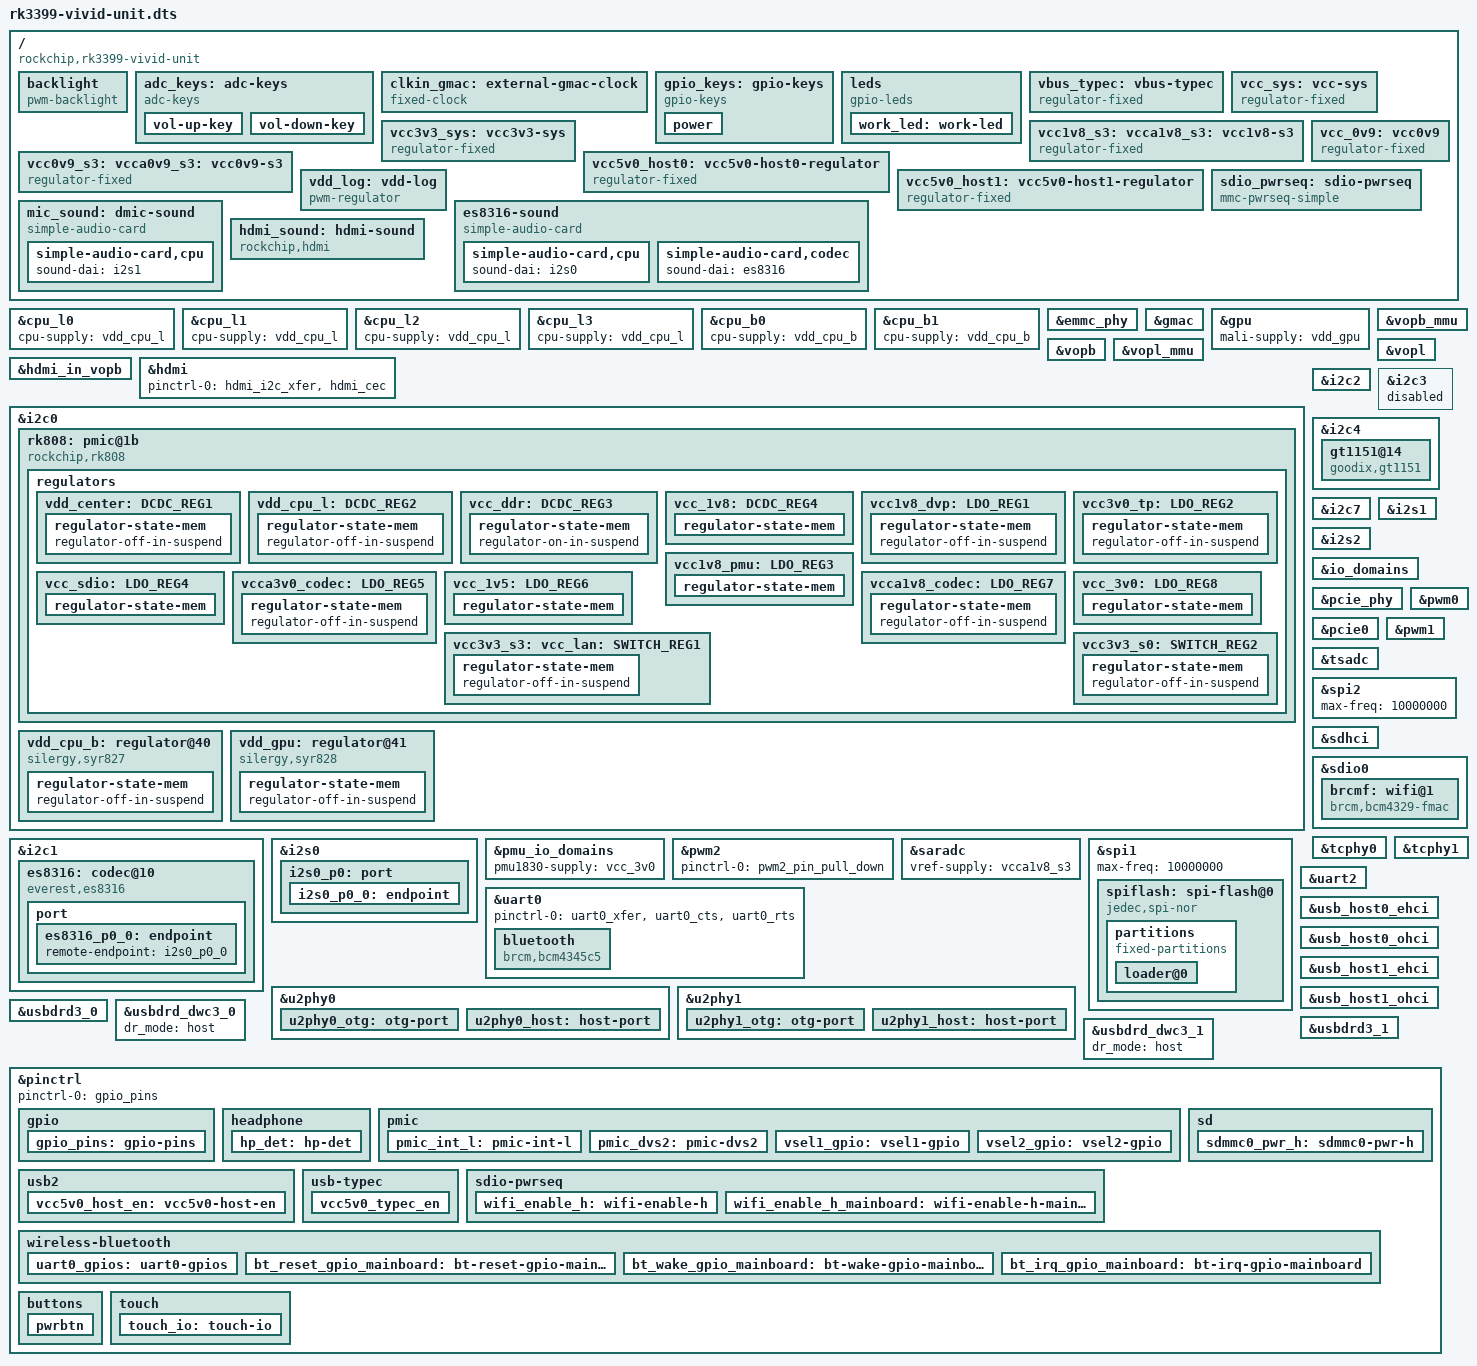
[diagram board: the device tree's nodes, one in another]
// SPDX-License-Identifier: (GPL-2.0+ OR MIT)
/*
 * Copyright (c) 2022 Biandenghuo Co., Ltd.
 */

/dts-v1/;
#include "dt-bindings/pwm/pwm.h"
#include "dt-bindings/input/input.h"
#include "rk3399.dtsi"
#include "rk3399-opp.dtsi"

/ {
	compatible = "rockchip,rk3399-vivid-unit", "rockchip,rk3399";

	backlight: backlight {
		compatible = "pwm-backlight";
		brightness-levels = <0 255>;
		num-interpolated-steps = <255>;
		default-brightness-level = <200>;
		pwms = <&pwm0 0 25000 0>, <&pwm1 0 1000000 0>;
	};

	adc_keys: adc-keys {
                compatible = "adc-keys";
                io-channels = <&saradc 1>;
                io-channel-names = "buttons";
                keyup-threshold-microvolt = <1800000>;
                poll-interval = <100>;

                vol-up-key {
                        label = "volume up";
                        linux,code = <KEY_VOLUMEUP>;
                        press-threshold-microvolt = <1000>;
                };

                vol-down-key {
                        label = "volume down";
                        linux,code = <KEY_VOLUMEDOWN>;
                        press-threshold-microvolt = <170000>;
                };
	};
	
	clkin_gmac: external-gmac-clock {
		compatible = "fixed-clock";
		clock-frequency = <125000000>;
		clock-output-names = "clkin_gmac";
		#clock-cells = <0>;
	};
	
	gpio_keys: gpio-keys {
                compatible = "gpio-keys";
                autorepeat;
                pinctrl-names = "default";
                pinctrl-0 = <&pwrbtn>;

                power {
                        debounce-interval = <100>;
                        gpios = <&gpio0 5 GPIO_ACTIVE_LOW>;
                        label = "GPIO Key Power";
                        linux,code = <KEY_POWER>;
                        wakeup-source;
                };
        };

	leds {
                status = "okay";
                compatible = "gpio-leds";
                work_led: work-led {
                        label = "work-led";
                        gpios = <&gpio4 21 GPIO_ACTIVE_LOW>; /*GPIO4_C5*/
                        linux,default-trigger = "mmc0";
                        default-state = "on";
                };
        };

	vbus_typec: vbus-typec {
		compatible = "regulator-fixed";
		regulator-name = "vbus_typec";
		regulator-always-on;
		regulator-boot-on;
		regulator-min-microvolt = <5000000>;
		regulator-max-microvolt = <5000000>;
	};
	
	vcc_sys: vcc-sys {
		compatible = "regulator-fixed";
		regulator-name = "vcc_sys";
		regulator-always-on;
		regulator-boot-on;
		regulator-min-microvolt = <5000000>;
		regulator-max-microvolt = <5000000>;
		vin-supply = <&vbus_typec>;
	};

	vcc3v3_sys: vcc3v3-sys {
		compatible = "regulator-fixed";
		regulator-name = "vcc3v3_sys";
		regulator-always-on;
		regulator-boot-on;
		regulator-min-microvolt = <3300000>;
		regulator-max-microvolt = <3300000>;
		vin-supply = <&vcc_sys>;
	};	
	
	/* switched by pmic_sleep */
	vcc1v8_s3: vcca1v8_s3: vcc1v8-s3 {
		compatible = "regulator-fixed";
		regulator-name = "vcc1v8_s3";
		regulator-always-on;
		regulator-boot-on;
		regulator-min-microvolt = <1800000>;
		regulator-max-microvolt = <1800000>;
		vin-supply = <&vcc_1v8>;
	};
	
	vcc_0v9: vcc0v9 {
		compatible = "regulator-fixed";
		regulator-name = "vcc0v9";
		regulator-always-on;
		regulator-boot-on;
		regulator-min-microvolt = <900000>;
		regulator-max-microvolt = <900000>;
		vin-supply = <&vcc3v3_sys>;
	};

	/* switched by pmic_sleep */
	vcc0v9_s3: vcca0v9_s3: vcc0v9-s3 {
		compatible = "regulator-fixed";
		regulator-name = "vcc0v9_s3";
		regulator-always-on;
		regulator-boot-on;
		regulator-min-microvolt = <900000>;
		regulator-max-microvolt = <900000>;
		vin-supply = <&vcc_0v9>;
	};
	
	vcc5v0_host0: vcc5v0-host0-regulator {
		compatible = "regulator-fixed";
		enable-active-high;
		gpio = <&gpio1 RK_PA0 GPIO_ACTIVE_HIGH>;
		pinctrl-names = "default";
		pinctrl-0 = <&vcc5v0_host_en>;
		regulator-name = "vcc5v0_host0";
		regulator-always-on;
		vin-supply = <&vcc_sys>;
	};
	
	vcc5v0_host1: vcc5v0-host1-regulator {
		compatible = "regulator-fixed";
		enable-active-high;
		gpio = <&gpio1 RK_PA3 GPIO_ACTIVE_HIGH>;
		pinctrl-names = "default";
		pinctrl-0 = <&vcc5v0_typec_en>;
		regulator-name = "vcc5v0_host1";
		regulator-always-on;
		vin-supply = <&vcc_sys>;
	};

	vdd_log: vdd-log {
		compatible = "pwm-regulator";
		pwms = <&pwm2 0 25000 1>;
		regulator-name = "vdd_log";
		regulator-always-on;
		regulator-boot-on;
		regulator-min-microvolt = <800000>;
		regulator-max-microvolt = <1400000>;
		vin-supply = <&vcc_sys>;
	};

	sdio_pwrseq: sdio-pwrseq {
                compatible = "mmc-pwrseq-simple";
                clocks = <&rk808 1>;
                clock-names = "ext_clock";
                pinctrl-names = "default";
                pinctrl-0 = <&wifi_enable_h>;
                reset-gpios = <&gpio0 10 GPIO_ACTIVE_LOW>; /* GPIO0_B2 */
        };

	mic_sound: dmic-sound {
                compatible = "simple-audio-card";
                simple-audio-card,format = "i2s";
                simple-audio-card,name = "rockchip,rk-mic-sound";
                simple-audio-card,mclk-fs = <256>;
                simple-audio-card,cpu {
                        sound-dai = <&i2s1>;
                };
        };

	es8316-sound {
                compatible = "simple-audio-card";
                simple-audio-card,format = "i2s";
                simple-audio-card,name = "rockchip,es8316-codec";
                simple-audio-card,mclk-fs = <256>;
                simple-audio-card,widgets =
                        "Microphone", "Mic Jack",
                        "Headphone", "Headphone Jack";
                simple-audio-card,routing =
                        "Mic Jack", "Mic Bias",
                        "MIC2", "Mic Jack",
                        "Headphone Jack", "HPOL",
                        "Headphone Jack", "HPOR";
                simple-audio-card,cpu {
                        sound-dai = <&i2s0>;
                };
                simple-audio-card,codec {
                        sound-dai = <&es8316>;
                };
        };

	hdmi_sound: hdmi-sound {
                status = "okay";
                compatible = "rockchip,hdmi";
                rockchip,mclk-fs = <256>;
                rockchip,card-name = "rockchip-hdmi0";
                rockchip,cpu = <&i2s2>;
                rockchip,codec = <&hdmi>;
                rockchip,jack-det;
        };
};

&cpu_l0 {
	cpu-supply = <&vdd_cpu_l>;
};

&cpu_l1 {
	cpu-supply = <&vdd_cpu_l>;
};

&cpu_l2 {
	cpu-supply = <&vdd_cpu_l>;
};

&cpu_l3 {
	cpu-supply = <&vdd_cpu_l>;
};

&cpu_b0 {
	cpu-supply = <&vdd_cpu_b>;
};

&cpu_b1 {
	cpu-supply = <&vdd_cpu_b>;
};

//&dsipanel {
//	reset-gpios = <&gpio4 29 GPIO_ACTIVE_LOW>;      /*GPIO4_D5*/
//	enable-gpios = <&gpio1 13 GPIO_ACTIVE_HIGH>;    /*GPIO1_B5*/
//
//	prepare-delay-ms = <20>;
//	reset-delay-ms = <20>;
//	init-delay-ms = <20>;
//	enable-delay-ms = <20>;
//	disable-delay-ms = <20>;
//	unprepare-delay-ms = <20>;
//};
//
//&dsi_in_vopl {
//	status = "okay";
//};

&emmc_phy {
	status = "okay";
};

&gmac {
	assigned-clocks = <&cru SCLK_RMII_SRC>;
	assigned-clock-parents = <&clkin_gmac>;
	clock_in_out = "input";
	phy-supply = <&vcc_lan>;
	phy-mode = "rgmii";
	pinctrl-names = "default";
	pinctrl-0 = <&rgmii_pins>;
	snps,reset-gpio = <&gpio3 RK_PB7 GPIO_ACTIVE_LOW>;
	snps,reset-active-low;
	snps,reset-delays-us = <0 10000 50000>;
	tx_delay = <0x28>;
	rx_delay = <0x11>;
	status = "okay";
};

&gpu {
	mali-supply = <&vdd_gpu>;
	status = "okay";
};

&vopb_mmu {
	status = "okay";
};

&vopb {
	status = "okay";
	assigned-clocks = <&cru DCLK_VOP0_DIV>;
	assigned-clock-parents = <&cru PLL_CPLL>;
};

&vopl_mmu {
	status = "okay";
};

&vopl {
	status = "okay";
	assigned-clocks = <&cru DCLK_VOP1_DIV>;
	assigned-clock-parents = <&cru PLL_VPLL>;
};

&hdmi_in_vopb {
	status = "okay";
};

&hdmi {
        pinctrl-names = "default";
        pinctrl-0 = <&hdmi_i2c_xfer>, <&hdmi_cec>;
        #address-cells = <1>;
        #size-cells = <0>;
        #sound-dai-cells = <0>;
        status = "okay";
};

&hdmi_sound {
        status = "okay";
};

&i2c0 {
	clock-frequency = <400000>; 
	i2c-scl-rising-time-ns = <168>;
	i2c-scl-falling-time-ns = <4>;
	status = "okay";

	rk808: pmic@1b {
		compatible = "rockchip,rk808";
		reg = <0x1b>;
		interrupt-parent = <&gpio1>;
		interrupts = <21 IRQ_TYPE_LEVEL_LOW>;
		#clock-cells = <1>;
		clock-output-names = "xin32k", "rk808-clkout2";
		pinctrl-names = "default";
		pinctrl-0 = <&pmic_int_l &pmic_dvs2>;
		rockchip,system-power-controller;
		wakeup-source;

		vcc1-supply = <&vcc3v3_sys>;
		vcc2-supply = <&vcc3v3_sys>;
		vcc3-supply = <&vcc3v3_sys>;
		vcc4-supply = <&vcc3v3_sys>;
		vcc6-supply = <&vcc3v3_sys>;
		vcc7-supply = <&vcc3v3_sys>;
		vcc8-supply = <&vcc3v3_sys>;
		vcc9-supply = <&vcc3v3_sys>;
		vcc10-supply = <&vcc3v3_sys>;
		vcc11-supply = <&vcc3v3_sys>;
		vcc12-supply = <&vcc3v3_sys>;
		vddio-supply = <&vcc_3v0>;

		regulators {
			vdd_center: DCDC_REG1 {
				regulator-name = "vdd_center";
				regulator-always-on;
				regulator-boot-on;
				regulator-min-microvolt = <750000>;
				regulator-max-microvolt = <1350000>;
				regulator-ramp-delay = <6001>;
				regulator-state-mem {
					regulator-off-in-suspend;
				};
			};

			vdd_cpu_l: DCDC_REG2 {
				regulator-name = "vdd_cpu_l";
				regulator-always-on;
				regulator-boot-on;
				regulator-min-microvolt = <750000>;
				regulator-max-microvolt = <1350000>;
				regulator-ramp-delay = <6001>;
				regulator-state-mem {
					regulator-off-in-suspend;
				};
			};

			vcc_ddr: DCDC_REG3 {
				regulator-name = "vcc_ddr";
				regulator-always-on;
				regulator-boot-on;
				regulator-state-mem {
					regulator-on-in-suspend;
				};
			};

			vcc_1v8: DCDC_REG4 {
				regulator-name = "vcc_1v8";
				regulator-always-on;
				regulator-boot-on;
				regulator-min-microvolt = <1800000>;
				regulator-max-microvolt = <1800000>;
				regulator-state-mem {
					regulator-on-in-suspend;
					regulator-suspend-microvolt = <1800000>;
				};
			};

			vcc1v8_dvp: LDO_REG1 {
				regulator-name = "vcc1v8_dvp";
				regulator-always-on;
				regulator-boot-on;
				regulator-min-microvolt = <1800000>;
				regulator-max-microvolt = <1800000>;
				regulator-state-mem {
					regulator-off-in-suspend;
				};
			};

			vcc3v0_tp: LDO_REG2 {
				regulator-name = "vcc3v0_tp";
				regulator-always-on;
				regulator-boot-on;
				regulator-min-microvolt = <3000000>;
				regulator-max-microvolt = <3000000>;
				regulator-state-mem {
					regulator-off-in-suspend;
				};
			};

			vcc1v8_pmu: LDO_REG3 {
				regulator-name = "vcc1v8_pmu";
				regulator-always-on;
				regulator-boot-on;
				regulator-min-microvolt = <1800000>;
				regulator-max-microvolt = <1800000>;
				regulator-state-mem {
					regulator-on-in-suspend;
					regulator-suspend-microvolt = <1800000>;
				};
			};

			vcc_sdio: LDO_REG4 {
				regulator-name = "vcc_sdio";
				regulator-always-on;
				regulator-boot-on;
				regulator-min-microvolt = <1800000>;
				regulator-max-microvolt = <3300000>;
				regulator-state-mem {
					regulator-on-in-suspend;
					regulator-suspend-microvolt = <3000000>;
				};
			};

			vcca3v0_codec: LDO_REG5 {
				regulator-name = "vcca3v0_codec";
				regulator-always-on;
				regulator-boot-on;
				regulator-min-microvolt = <3000000>;
				regulator-max-microvolt = <3000000>;
				regulator-state-mem {
					regulator-off-in-suspend;
				};
			};

			vcc_1v5: LDO_REG6 {
				regulator-name = "vcc_1v5";
				regulator-always-on;
				regulator-boot-on;
				regulator-min-microvolt = <1500000>;
				regulator-max-microvolt = <1500000>;
				regulator-state-mem {
					regulator-on-in-suspend;
					regulator-suspend-microvolt = <1500000>;
				};
			};

			vcca1v8_codec: LDO_REG7 {
				regulator-name = "vcca1v8_codec";
				regulator-always-on;
				regulator-boot-on;
				regulator-min-microvolt = <1800000>;
				regulator-max-microvolt = <1800000>;
				regulator-state-mem {
					regulator-off-in-suspend;
				};
			};

			vcc_3v0: LDO_REG8 {
				regulator-name = "vcc_3v0";
				regulator-always-on;
				regulator-boot-on;
				regulator-min-microvolt = <3000000>;
				regulator-max-microvolt = <3000000>;
				regulator-state-mem {
					regulator-on-in-suspend;
					regulator-suspend-microvolt = <3000000>;
				};
			};

			vcc3v3_s3: vcc_lan: SWITCH_REG1 {
				regulator-name = "vcc3v3_s3";
				regulator-always-on;
				regulator-boot-on;
				regulator-state-mem {
					regulator-off-in-suspend;
				};
			};

			vcc3v3_s0: SWITCH_REG2 {
				regulator-name = "vcc3v3_s0";
				regulator-always-on;
				regulator-boot-on;
				regulator-state-mem {
					regulator-off-in-suspend;
				};
			};
		};
	};

	vdd_cpu_b: regulator@40 {
		compatible = "silergy,syr827";
		reg = <0x40>;
		fcs,suspend-voltage-selector = <1>;
                regulator-compatible = "fan53555-reg";
                pinctrl-names = "default";
                pinctrl-0 = <&vsel1_gpio>;
                vsel-gpios = <&gpio1 17 GPIO_ACTIVE_HIGH>;
                regulator-initial-state = <3>;
		regulator-name = "vdd_cpu_b";
		regulator-min-microvolt = <712500>;
		regulator-max-microvolt = <1500000>;
		regulator-ramp-delay = <1000>;
		regulator-always-on;
		regulator-boot-on;
		vin-supply = <&vcc_sys>;

		regulator-state-mem {
			regulator-off-in-suspend;
		};
	};

	vdd_gpu: regulator@41 {
		compatible = "silergy,syr828";
		reg = <0x41>;
                regulator-compatible = "fan53555-reg";
                pinctrl-names = "default";
                pinctrl-0 = <&vsel2_gpio>;
                vsel-gpios = <&gpio1 14 GPIO_ACTIVE_HIGH>;
                regulator-initial-state = <3>;
		fcs,suspend-voltage-selector = <1>;
		regulator-name = "vdd_gpu";
		regulator-min-microvolt = <712500>;
		regulator-max-microvolt = <1500000>;
		regulator-ramp-delay = <1000>;
		regulator-always-on;
		regulator-boot-on;
		vin-supply = <&vcc_sys>;

		regulator-state-mem {
			regulator-off-in-suspend;
		};
	};
};

&i2c1 {
	status = "okay";
	i2c-scl-rising-time-ns = <300>;
	i2c-scl-falling-time-ns = <15>;
	
       	es8316: codec@10 {
                compatible = "everest,es8316";
                reg = <0x10>;
                clocks = <&cru SCLK_I2S_8CH_OUT>;
                clock-names = "mclk";
                #sound-dai-cells = <0>;
                spk-con-gpio = <&gpio3 29 GPIO_ACTIVE_HIGH>;
		hp-det-gpio = <&gpio3 30 GPIO_ACTIVE_HIGH>; /*HP_DET GPIO3_D6*/	
		
		port {
			es8316_p0_0: endpoint {
				remote-endpoint = <&i2s0_p0_0>;
			};
		};
        };
};

&i2c2 {
	status = "okay";
};

&i2c3 {
	i2c-scl-rising-time-ns = <450>;
	i2c-scl-falling-time-ns = <15>;
	status = "disabled";
};

&i2c4 {
	i2c-scl-rising-time-ns = <600>;
	i2c-scl-falling-time-ns = <20>;
	status = "okay";
	
	gt1151@14 {
	    compatible = "goodix,gt1151";
	    reg = <0x14>;
	    interupt-parent = <&gpio1>;
	    interrupts = <&gpio1 20>;
	    irq-gpios = <&gpio1 20 IRQ_TYPE_EDGE_FALLING>; /*GPIO1_C4*/
	    rst-gpios = <&gpio0 12 GPIO_ACTIVE_LOW>; /*GPIO0_B4*/
            pinctrl-names = "default";
            pinctrl-0 = <&touch_io>;
	    power-supply = <&vcc3v0_tp>;
	};
};

&i2c7 {
	status = "okay";
};

&i2s0 {
        rockchip,playback-channels = <2>;
        rockchip,capture-channels = <2>;
	pinctrl-0 = <&i2s0_2ch_bus>;
	pinctrl-names = "default";
        status = "okay";
		
	i2s0_p0: port {
		i2s0_p0_0: endpoint {
			dai-format = "i2s";
			mclk-fs = <256>;
			remote-endpoint = <&es8316_p0_0>;
		};
	};
	
};

&i2s1 {

	dma-names = "rx"; // only has capture
	rockchip,playback-channels = <0>;
	rockchip,capture-channels = <2>;
	status = "okay";
};

&i2s2 {
	#sound-dai-cells = <0>;
	status = "okay";
};

/*
	bt656-supply:  The supply connected to APIO2_VDD.
	audio-supply:  The supply connected to APIO5_VDD.
	sdmmc-supply:  The supply connected to SDMMC0_VDD.
	gpio1830-supply:  The supply connected to APIO4_VDD.
	pmu1830-supply:The supply connected to PMUIO2_VDD.
*/


&io_domains {
	status = "okay";

	bt656-supply = <&vcc_1v8>; //vivid
	audio-supply = <&vcca1v8_codec>;
	sdmmc-supply = <&vcc_sdio>;
	gpio1830-supply = <&vcc_3v0>;
};

&pcie_phy {
	status = "okay";
};

&pcie0 {
	ep-gpios = <&gpio4 RK_PD3 GPIO_ACTIVE_HIGH>;
	max-link-speed = <2>;
	num-lanes = <4>;
	pinctrl-0 = <&pcie_clkreqnb_cpm>;
	pinctrl-names = "default";
	vpcie0v9-supply = <&vcca0v9_s3>;
	vpcie1v8-supply = <&vcca1v8_s3>;
	vpcie3v3-supply = <&vcc3v3_sys>;
	status = "okay";
};

&pmu_io_domains {
	pmu1830-supply = <&vcc_3v0>;
	status = "okay";
};

&pwm0 {
	status = "okay";
};

&pwm1 {
	status = "okay";
};

&pwm2 {
	status = "okay";
	pinctrl-names = "active";
	pinctrl-0 = <&pwm2_pin_pull_down>;
};

&saradc {
	vref-supply = <&vcca1v8_s3>;
	status = "okay";
};

&tsadc {
	/* tshut mode 0:CRU 1:GPIO */
	rockchip,hw-tshut-mode = <1>;
	/* tshut polarity 0:LOW 1:HIGH */
	rockchip,hw-tshut-polarity = <1>;
	status = "okay";
};

&spi1 {
	status = "okay";
	max-freq = <10000000>;
	#address-cells = <1>;
	#size-cells = <0>;
	
	spiflash: spi-flash@0 {
	        #address-cells = <0x1>;
	        #size-cells = <1>;
	        compatible = "jedec,spi-nor";
	        reg = <0x0>;
	        spi-max-frequency = <10000000>;
	        status = "okay";
	
	        partitions {
	                compatible = "fixed-partitions";
	                #address-cells = <1>;
	                #size-cells = <1>;
	
	                loader@0 {
	                        label = "loader";
	                        reg = <0x0 0x1000000>;
	                };
	        };
	};
};

&spi2 {
	status = "okay";
	max-freq = <10000000>;

};

&sdhci {/*eMMC FE330000*/
	bus-width = <8>;
	assigned-clock-rates = <150000000>;
	mmc-hs400-1_8v;
	no-sdio;
	no-sd;
	non-removable;
	keep-power-in-suspend;
	mmc-hs400-enhanced-strobe;
	status = "okay";
};

//SD Card FE320000
//&sdmmc {
//	broken-cd;
//	bus-width = <4>;
//	cap-mmc-highspeed;
//	cap-sd-highspeed;
//	no-sdio;
//	no-emmc;
//	clock-frequency = <150000000>;
//	disable-wp;
//	sd-uhs-sdr104;
//	max-frequency = <150000000>;
//	pinctrl-names = "default";
//	pinctrl-0 = <&sdmmc_clk &sdmmc_cmd &sdmmc_cd &sdmmc_bus4>;
//	vmmc-supply = <&vcc3v0_sd>;
//	vqmmc-supply = <&vcc_sdio>;
//	status = "okay"; //didn'tn disable as the usb2.0 host will have issue  <--- ???????
//};

&sdio0 {/*SDIO port FE310000*/
	#address-cells = <1>;
	#size-cells = <0>;
	clock-frequency = <50000000>;
	bus-width = <4>;
	disable-wp;
	cap-sd-highspeed;
	cap-sdio-irq;
	keep-power-in-suspend;
	mmc-pwrseq = <&sdio_pwrseq>;
	non-removable;
	num-slots = <1>;
	pinctrl-names = "default";
	pinctrl-0 = <&sdio0_bus4 &sdio0_cmd &sdio0_clk>;
	sd-uhs-sdr104;  /*SD3.0 Support need WIFI IO Power 1.8V*/
	status = "okay";
	
	brcmf: wifi@1 {
		compatible = "brcm,bcm4329-fmac";
		reg = <1>;
		interrupt-parent = <&gpio0>;
		interrupts = <RK_PA3 IRQ_TYPE_LEVEL_HIGH>;
		interrupt-names = "host-wake";
		pinctrl-names = "default";
//		pinctrl-0 = <&wifi_host_wake_l>;
	};
};

&tcphy0 { /* Type-C USB3.0 OTG PHY */
	status = "okay";
};

&tcphy1 { /* Type-C USB3.0 HOST PHY, not need extcon */
	status = "okay";
};

&uart0 {
	pinctrl-names = "default";
	pinctrl-0 = <&uart0_xfer &uart0_cts &uart0_rts>;
	status = "okay";

	bluetooth {
		compatible = "brcm,bcm4345c5";
		clocks = <&rk808 1>;
		clock-names = "lpo";
		device-wakeup-gpios = <&gpio2 26 GPIO_ACTIVE_HIGH>; /* GPIO2_D2 BT_WAKE_L */
		host-wakeup-gpios = <&gpio0 4 GPIO_ACTIVE_HIGH>; /* GPIO0_A4 BT_HOST_WAKE_L */
		reset-gpios = <&gpio0 9 GPIO_ACTIVE_HIGH>; /* GPIO0_B1 BT_REG_ON*/
		pinctrl-names = "default";
		pinctrl-0 = <&bt_reset_gpio_mainboard>, <&bt_wake_gpio_mainboard>, <&bt_irq_gpio_mainboard>;
	};
};

&uart2 {
	status = "okay";
};

&u2phy0 {
	status = "okay";
	u2phy0_otg: otg-port {   /* USB2.0 Type-C PHY */
		status = "okay";
	};

	u2phy0_host: host-port { /* USB2.0 Host PHY */
		/*phy-supply = <&vcc5v0_host>;*/
		status = "okay";
	};
};

&u2phy1 { /* USB2.0 Type-A PHY */
	status = "okay";

	u2phy1_otg: otg-port {  /* USB2.0 Type-C PHY */
		status = "okay";
	};

	u2phy1_host: host-port { /* USB2.0 Host PHY*/
		/*phy-supply = <&vcc5v0_host>;*/
		status = "okay";
	};
};

&usb_host0_ehci { /* USB2.0 Controler */
	status = "okay";
};

&usb_host0_ohci {
	status = "okay";
};

&usb_host1_ehci {
	status = "okay";
};

&usb_host1_ohci {
	status = "okay";
};

&usbdrd3_0 { /* Type-C0 USB3.0 Controler*/
	status = "okay";
};

&usbdrd_dwc3_0 { /* USB3.0 Controler Sub node*/
	status = "okay";
	dr_mode = "host"; /*otg*/
};

&usbdrd3_1 { /* Type-C1 USB3.0 Controler*/
	status = "okay";
};

&usbdrd_dwc3_1 { /* USB3.0 Controler Sub node*/
	status = "okay";
	dr_mode = "host";
};

&pinctrl {

	pinctrl-names = "default";
	pinctrl-0 = <&gpio_pins>;

	gpio {
                gpio_pins: gpio-pins {
                        rockchip,pins =
                                <1 RK_PA1 RK_FUNC_GPIO &pcfg_pull_down>,
                                <1 RK_PA2 RK_FUNC_GPIO &pcfg_pull_down>,
                                <1 RK_PA4 RK_FUNC_GPIO &pcfg_pull_down>,
                                <2 RK_PA2 RK_FUNC_GPIO &pcfg_pull_down>,
                                <2 RK_PA3 RK_FUNC_GPIO &pcfg_pull_down>,
                                <2 RK_PA4 RK_FUNC_GPIO &pcfg_pull_down>,
                                <2 RK_PA5 RK_FUNC_GPIO &pcfg_pull_down>,
                                <2 RK_PA6 RK_FUNC_GPIO &pcfg_pull_down>,
                                <2 RK_PD3 RK_FUNC_GPIO &pcfg_pull_down>,
                                <4 RK_PB0 RK_FUNC_GPIO &pcfg_pull_down>,
                                <4 RK_PB1 RK_FUNC_GPIO &pcfg_pull_down>,
                                <4 RK_PB2 RK_FUNC_GPIO &pcfg_pull_down>,
                                <4 RK_PB3 RK_FUNC_GPIO &pcfg_pull_down>,
                                <4 RK_PB4 RK_FUNC_GPIO &pcfg_pull_down>,
                                <4 RK_PB5 RK_FUNC_GPIO &pcfg_pull_down>,
                                <4 RK_PD1 RK_FUNC_GPIO &pcfg_pull_down>,
                                <4 RK_PD2 RK_FUNC_GPIO &pcfg_pull_down>,
                                <4 RK_PD6 RK_FUNC_GPIO &pcfg_pull_down>;
                };
        };

	headphone {
	        hp_det: hp-det {
	            rockchip,pins =
	                <3 RK_PD6 RK_FUNC_GPIO &pcfg_pull_none>;
	        };
	};
	
        pmic {
                pmic_int_l: pmic-int-l {
                        rockchip,pins =
                                <1 RK_PC5 RK_FUNC_GPIO &pcfg_pull_up>;
                };

                pmic_dvs2: pmic-dvs2 {
                        rockchip,pins =
                                <1 RK_PC2 RK_FUNC_GPIO &pcfg_pull_down>;
                };

                vsel1_gpio: vsel1-gpio {
                        rockchip,pins = <1 RK_PC1 RK_FUNC_GPIO &pcfg_pull_down>;
                };

                vsel2_gpio: vsel2-gpio {
                        rockchip,pins = <1 RK_PB6 RK_FUNC_GPIO &pcfg_pull_down>;
                };
        };

        sd {
                sdmmc0_pwr_h: sdmmc0-pwr-h {
                        rockchip,pins =
                                <0 RK_PA1 RK_FUNC_GPIO &pcfg_pull_none>;
                };
        };

	usb2 {
        	vcc5v0_host_en: vcc5v0-host-en {
			rockchip,pins = <1 RK_PA0 RK_FUNC_GPIO &pcfg_pull_none>;
        	};
	};

	usb-typec {
		vcc5v0_typec_en: vcc5v0_typec_en {
			rockchip,pins = <1 RK_PA3 RK_FUNC_GPIO &pcfg_pull_up>;
		};
	};

        sdio-pwrseq {
                wifi_enable_h: wifi-enable-h {
                        rockchip,pins =
                                <0 RK_PB2 RK_FUNC_GPIO &pcfg_pull_none>;
                };

                wifi_enable_h_mainboard: wifi-enable-h-mainboard {
                        rockchip,pins =
                                <0 RK_PA3 RK_FUNC_GPIO &pcfg_pull_none>;
                };
        };

        wireless-bluetooth {
                uart0_gpios: uart0-gpios {
                        rockchip,pins =
                                <2 RK_PC3 RK_FUNC_GPIO &pcfg_pull_none>;
                };
                bt_reset_gpio_mainboard: bt-reset-gpio-mainboard {
                        rockchip,pins =
                                <0 RK_PB1 RK_FUNC_GPIO &pcfg_pull_none>;
                };
                bt_wake_gpio_mainboard: bt-wake-gpio-mainboard {
                        rockchip,pins =
                                <2 RK_PD2 RK_FUNC_GPIO &pcfg_pull_none>;
                };
                bt_irq_gpio_mainboard: bt-irq-gpio-mainboard {
                        rockchip,pins =
                                <0 RK_PA4 RK_FUNC_GPIO &pcfg_pull_down>;
                };
        };

	buttons {
                pwrbtn: pwrbtn {
                        rockchip,pins = <0 RK_PA5 RK_FUNC_GPIO &pcfg_pull_up>;
                };
        };

	touch {
                touch_io: touch-io {
                        rockchip,pins = <1 RK_PC4 RK_FUNC_GPIO &pcfg_pull_up>,
                        		<0 RK_PB4 RK_FUNC_GPIO &pcfg_pull_up>;
                };
        };
};
